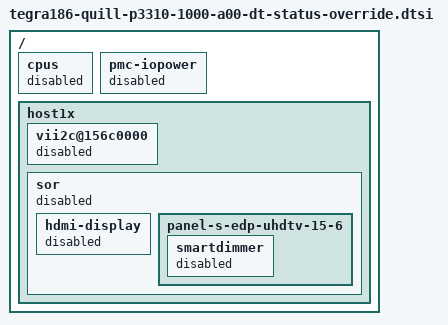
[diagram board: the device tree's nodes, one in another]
/*
 * tegra186-quill-p3310-1000-a00-dt-status-override.dtsi:
 *
 * Copyright (c) 2015, NVIDIA CORPORATION.  All rights reserved.
 *
 * This program is free software; you can redistribute it and/or modify
 * it under the terms of the GNU General Public License as published by
 * the Free Software Foundation; version 2 of the License.
 *
 * This program is distributed in the hope that it will be useful, but WITHOUT
 * ANY WARRANTY; without even the implied warranty of MERCHANTABILITY or
 * FITNESS FOR A PARTICULAR PURPOSE.  See the GNU General Public License for
 * more details.
 */

/ {
	cpus {
		status = "disabled";
	};

	pmc-iopower {
		status = "disabled";
	};

	host1x {
		vii2c@156c0000 {
			status = "disabled";
		};

		sor {
			status = "disabled";
			hdmi-display {
				status = "disabled";
			};

			panel-s-edp-uhdtv-15-6 {
				smartdimmer {
					status = "disabled";
				};
			};
		};
	};
};

